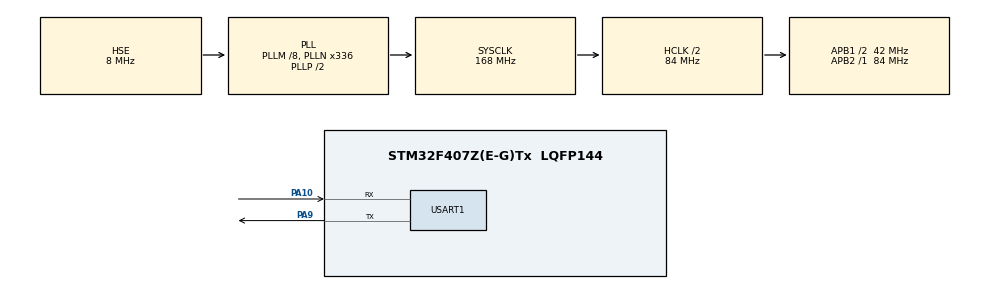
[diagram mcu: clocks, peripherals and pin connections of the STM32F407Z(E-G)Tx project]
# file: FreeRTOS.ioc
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FREERTOS.BinarySemaphores01=myBinarySem01,Dynamic,NULL
FREERTOS.Mutexes01=myMutex01,Dynamic,NULL
FREERTOS.Tasks01=defaultTask,0,512,StartDefaultTask,Default,NULL,Dynamic,NULL,NULL;myTask02,1,512,StartTask02,Default,NULL,Dynamic,NULL,NULL;myTask03,2,512,StartTask03,Default,NULL,Dynamic,NULL,NULL
FREERTOS.Timers01=myTimer01,Callback01,osTimerPeriodic,Default,NULL,Dynamic,NULL
FREERTOS.configTIMER_TASK_PRIORITY=5
FREERTOS.configUSE_TIMERS=1
Mcu.Family=STM32F4
Mcu.Name=STM32F407Z(E-G)Tx
Mcu.Package=LQFP144
NVIC.PriorityGroup=NVIC_PRIORITYGROUP_4
NVIC.TIM1_UP_TIM10_IRQn=true\:0\:0\:false\:false\:true\:false\:false\:true
NVIC.TimeBase=TIM1_UP_TIM10_IRQn
NVIC.TimeBaseIP=TIM1
NVIC.USART1_IRQn=true\:5\:0\:false\:false\:true\:true\:true\:true
PA10.Mode=Asynchronous
PA10.Signal=USART1_RX
PA9.Mode=Asynchronous
PA9.Signal=USART1_TX
PH0-OSC_IN.Mode=HSE-External-Oscillator
PH0-OSC_IN.Signal=RCC_OSC_IN
PH1-OSC_OUT.Mode=HSE-External-Oscillator
PH1-OSC_OUT.Signal=RCC_OSC_OUT
ProjectManager.HeapSize=0x200
ProjectManager.StackSize=0x400
ProjectManager.TargetToolchain=MDK-ARM V5.27
RCC.48MHZClocksFreq_Value=84000000
RCC.AHBCLKDivider=RCC_SYSCLK_DIV2
RCC.AHBFreq_Value=84000000
RCC.APB1CLKDivider=RCC_HCLK_DIV2
RCC.APB1Freq_Value=42000000
RCC.APB1TimFreq_Value=84000000
RCC.APB2Freq_Value=84000000
RCC.APB2TimFreq_Value=84000000
RCC.CortexFreq_Value=84000000
RCC.HCLKFreq_Value=84000000
RCC.HSE_VALUE=8000000
RCC.HSI_VALUE=16000000
RCC.LSE_VALUE=32768
RCC.PLLM=8
RCC.PLLN=336
RCC.PLLSourceVirtual=RCC_PLLSOURCE_HSE
RCC.SYSCLKFreq_VALUE=168000000
RCC.SYSCLKSource=RCC_SYSCLKSOURCE_PLLCLK
RCC.VCOOutputFreq_Value=336000000
USART1.VirtualMode=VM_ASYNC
VP_FREERTOS_VS_CMSIS_V1.Mode=CMSIS_V1
VP_SYS_VS_tim1.Mode=TIM1
board=custom

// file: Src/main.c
/* USER CODE BEGIN Header */
/**
  ******************************************************************************
  * @file           : main.c
  * @brief          : Main program body
  ******************************************************************************
  * @attention
  *
  * <h2><center>&copy; Copyright (c) 2020 STMicroelectronics.
  * All rights reserved.</center></h2>
  *
  * This software component is licensed by ST under Ultimate Liberty license
  * SLA0044, the "License"; You may not use this file except in compliance with
  * the License. You may obtain a copy of the License at:
  *                             www.st.com/SLA0044
  *
  ******************************************************************************
  */
/* USER CODE END Header */

#include "main.h"
#include "cmsis_os.h"
#include "usart.h"
#include "gpio.h"

void SystemClock_Config(void);
void MX_FREERTOS_Init(void);

int main(void)
{

  /* MCU Configuration--------------------------------------------------------*/

  /* Reset of all peripherals, Initializes the Flash interface and the Systick. */
  HAL_Init();

  /* Configure the system clock */
  SystemClock_Config();

  /* Initialize all configured peripherals */
  MX_GPIO_Init();
  MX_USART1_UART_Init();

  /* Call init function for freertos objects (in freertos.c) */
  MX_FREERTOS_Init();
  /* Start scheduler */
  osKernelStart();

  /* We should never get here as control is now taken by the scheduler */
  /* Infinite loop */
  while (1)
  {

  }
}

void SystemClock_Config(void)
{
  RCC_OscInitTypeDef RCC_OscInitStruct = {0};
  RCC_ClkInitTypeDef RCC_ClkInitStruct = {0};

  /** Configure the main internal regulator output voltage
  */
  __HAL_RCC_PWR_CLK_ENABLE();
  __HAL_PWR_VOLTAGESCALING_CONFIG(PWR_REGULATOR_VOLTAGE_SCALE1);
  /** Initializes the CPU, AHB and APB busses clocks
  */
  RCC_OscInitStruct.OscillatorType = RCC_OSCILLATORTYPE_HSE;
  RCC_OscInitStruct.HSEState = RCC_HSE_ON;
  RCC_OscInitStruct.PLL.PLLState = RCC_PLL_ON;
  RCC_OscInitStruct.PLL.PLLSource = RCC_PLLSOURCE_HSE;
  RCC_OscInitStruct.PLL.PLLM = 8;
  RCC_OscInitStruct.PLL.PLLN = 336;
  RCC_OscInitStruct.PLL.PLLP = RCC_PLLP_DIV2;
  RCC_OscInitStruct.PLL.PLLQ = 4;
  if (HAL_RCC_OscConfig(&RCC_OscInitStruct) != HAL_OK)
  {
    Error_Handler();
  }
  /** Initializes the CPU, AHB and APB busses clocks
  */
  RCC_ClkInitStruct.ClockType = RCC_CLOCKTYPE_HCLK|RCC_CLOCKTYPE_SYSCLK
                              |RCC_CLOCKTYPE_PCLK1|RCC_CLOCKTYPE_PCLK2;
  RCC_ClkInitStruct.SYSCLKSource = RCC_SYSCLKSOURCE_PLLCLK;
  RCC_ClkInitStruct.AHBCLKDivider = RCC_SYSCLK_DIV2;
  RCC_ClkInitStruct.APB1CLKDivider = RCC_HCLK_DIV2;
  RCC_ClkInitStruct.APB2CLKDivider = RCC_HCLK_DIV1;

  if (HAL_RCC_ClockConfig(&RCC_ClkInitStruct, FLASH_LATENCY_2) != HAL_OK)
  {
    Error_Handler();
  }
}

 /**
  * @brief  Period elapsed callback in non blocking mode
  * @note   This function is called  when TIM1 interrupt took place, inside
  * HAL_TIM_IRQHandler(). It makes a direct call to HAL_IncTick() to increment
  * a global variable "uwTick" used as application time base.
  * @param  htim : TIM handle
  * @retval None
  */
void HAL_TIM_PeriodElapsedCallback(TIM_HandleTypeDef *htim)
{
  if (htim->Instance == TIM1) {
    HAL_IncTick();
  }
}

void Error_Handler(void)
{
}

/************************ (C) COPYRIGHT STMicroelectronics *****END OF FILE****/

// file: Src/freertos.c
/* USER CODE BEGIN Header */
/**
  ******************************************************************************
  * File Name          : freertos.c
  * Description        : Code for freertos applications
  ******************************************************************************
  * @attention
  *
  * <h2><center>&copy; Copyright (c) 2020 STMicroelectronics.
  * All rights reserved.</center></h2>
  *
  * This software component is licensed by ST under Ultimate Liberty license
  * SLA0044, the "License"; You may not use this file except in compliance with
  * the License. You may obtain a copy of the License at:
  *                             www.st.com/SLA0044
  *
  ******************************************************************************
  */
/* USER CODE END Header */

#include "FreeRTOS.h"
#include "task.h"
#include "main.h"
#include "cmsis_os.h"

/* USER CODE BEGIN Includes */
#include "usart.h"
/* USER CODE END Includes */

/* USER CODE BEGIN Variables */
EventGroupHandle_t Event_Handle =NULL;//事件标志组
/* USER CODE END Variables */
osThreadId defaultTaskHandle;
osThreadId myTask02Handle;
osThreadId myTask03Handle;
osTimerId myTimer01Handle;					//软件定时器
osMutexId myMutex01Handle;					//互斥信号量
osSemaphoreId myBinarySem01Handle;	//二值信号量

/* USER CODE BEGIN FunctionPrototypes */
#define EVENT  (0x01 << 7)//设置事件掩码的位1
/* USER CODE END FunctionPrototypes */

void StartDefaultTask(void const * argument);
void StartTask02(void const * argument);
void StartTask03(void const * argument);
void Callback01(void const * argument);

void MX_FREERTOS_Init(void); /* (MISRA C 2004 rule 8.1) */

/* GetIdleTaskMemory prototype (linked to static allocation support) */
void vApplicationGetIdleTaskMemory( StaticTask_t **ppxIdleTaskTCBBuffer, StackType_t **ppxIdleTaskStackBuffer, uint32_t *pulIdleTaskStackSize );

/* GetTimerTaskMemory prototype (linked to static allocation support) */
void vApplicationGetTimerTaskMemory( StaticTask_t **ppxTimerTaskTCBBuffer, StackType_t **ppxTimerTaskStackBuffer, uint32_t *pulTimerTaskStackSize );

/* USER CODE BEGIN GET_IDLE_TASK_MEMORY */
static StaticTask_t xIdleTaskTCBBuffer;
static StackType_t xIdleStack[configMINIMAL_STACK_SIZE];

void vApplicationGetIdleTaskMemory( StaticTask_t **ppxIdleTaskTCBBuffer, StackType_t **ppxIdleTaskStackBuffer, uint32_t *pulIdleTaskStackSize )
{
  *ppxIdleTaskTCBBuffer = &xIdleTaskTCBBuffer;
  *ppxIdleTaskStackBuffer = &xIdleStack[0];
  *pulIdleTaskStackSize = configMINIMAL_STACK_SIZE;
  /* place for user code */
}
/* USER CODE END GET_IDLE_TASK_MEMORY */

/* USER CODE BEGIN GET_TIMER_TASK_MEMORY */
static StaticTask_t xTimerTaskTCBBuffer;
static StackType_t xTimerStack[configTIMER_TASK_STACK_DEPTH];

void vApplicationGetTimerTaskMemory( StaticTask_t **ppxTimerTaskTCBBuffer, StackType_t **ppxTimerTaskStackBuffer, uint32_t *pulTimerTaskStackSize )
{
  *ppxTimerTaskTCBBuffer = &xTimerTaskTCBBuffer;
  *ppxTimerTaskStackBuffer = &xTimerStack[0];
  *pulTimerTaskStackSize = configTIMER_TASK_STACK_DEPTH;
  /* place for user code */
}
/* USER CODE END GET_TIMER_TASK_MEMORY */

void MX_FREERTOS_Init(void) {
  /* Create the mutex(es) */
  /* definition and creation of myMutex01 */
  osMutexDef(myMutex01);
  myMutex01Handle = osMutexCreate(osMutex(myMutex01));

  /* Create the semaphores(s) */
  /* definition and creation of myBinarySem01 */
  osSemaphoreDef(myBinarySem01);
  myBinarySem01Handle = osSemaphoreCreate(osSemaphore(myBinarySem01), 1);

  /* Create the timer(s) */
  /* definition and creation of myTimer01 */
  osTimerDef(myTimer01, Callback01);
  myTimer01Handle = osTimerCreate(osTimer(myTimer01), osTimerPeriodic, NULL);

  /* Create the thread(s) */
  /* definition and creation of defaultTask */
  osThreadDef(defaultTask, StartDefaultTask, osPriorityNormal, 0, 512);
  defaultTaskHandle = osThreadCreate(osThread(defaultTask), NULL);

  /* definition and creation of myTask02 */
  osThreadDef(myTask02, StartTask02, osPriorityAboveNormal, 0, 512);
  myTask02Handle = osThreadCreate(osThread(myTask02), NULL);

  /* definition and creation of myTask03 */
  osThreadDef(myTask03, StartTask03, osPriorityHigh, 0, 512);
  myTask03Handle = osThreadCreate(osThread(myTask03), NULL);

  /* USER CODE BEGIN RTOS_THREADS */
  /* add threads, ... */
  Event_Handle = xEventGroupCreate();
  if(NULL != Event_Handle)
    printf("Event_Handle 事件创建成功!\r\n");
  /* USER CODE END RTOS_THREADS */

}

void StartDefaultTask(void const * argument)
{
  /* USER CODE BEGIN StartDefaultTask */
  /* Infinite loop */
  for(;;)
  {
		printf("任务1等待互斥信号量\n");
		osMutexWait(myMutex01Handle,osWaitForever);
//		osSemaphoreWait(myBinarySem01Handle,osWaitForever);  //等待二值信号量
		printf("任务1接收到互斥信号量\n");
		osDelay(5000);
		printf("任务1释放互斥信号量\n");
		osMutexRelease(myMutex01Handle);
//		osSemaphoreRelease(myBinarySem01Handle,osWaitForever); //释放二值信号量
  }
  /* USER CODE END StartDefaultTask */
}

void StartTask02(void const * argument)
{
  /* USER CODE BEGIN StartTask02 */
	EventBits_t r_event;  /* 定义一个事件接收变量 */
  /* Infinite loop */
  for(;;)
  {
    /*******************************************************************
     * 等待接收事件标志
     *
     * 如果xClearOnExit设置为pdTRUE，那么在xEventGroupWaitBits()返回之前，
     * 如果满足等待条件（如果函数返回的原因不是超时），那么在事件组中设置
     * 的uxBitsToWaitFor中的任何位都将被清除。
     * 如果xClearOnExit设置为pdFALSE，
     * 则在调用xEventGroupWaitBits()时，不会更改事件组中设置的位。
     *
     * xWaitForAllBits如果xWaitForAllBits设置为pdTRUE，则当uxBitsToWaitFor中
     * 的所有位都设置或指定的块时间到期时，xEventGroupWaitBits()才返回。
     * 如果xWaitForAllBits设置为pdFALSE，则当设置uxBitsToWaitFor中设置的任何
     * 一个位置1 或指定的块时间到期时，xEventGroupWaitBits()都会返回。
     * 阻塞时间由xTicksToWait参数指定。
      *********************************************************/
    r_event = xEventGroupWaitBits(Event_Handle,  /* 事件对象句柄 */
                                  EVENT,/* 接收线程感兴趣的事件 */
                                  pdTRUE,   /* 退出时清除事件位 */
                                  pdTRUE,   /* 满足感兴趣的所有事件 */
                                  portMAX_DELAY);/* 指定超时事件,一直等 */
		if((r_event & EVENT) == EVENT)
		{
			printf("\n\r清空任务事件标志组\n\r");
			xEventGroupClearBits(Event_Handle,EVENT);
		}
//		printf("任务2正在进行\n");
//    osDelay(1000);
  }
  /* USER CODE END StartTask02 */
}

void StartTask03(void const * argument)
{
  /* USER CODE BEGIN StartTask03 */
  /* Infinite loop */
  for(;;)
  {
		printf("\n\r开启软件定时器,1s进入一次回调函数\n\r");
		osTimerStart(myTimer01Handle,1000);
		printf("任务3等待互斥信号量\n");
		osMutexWait(myMutex01Handle,osWaitForever);
		printf("任务3接收到互斥信号量\n");
		printf("任务3释放互斥信号量\n");
		osMutexRelease(myMutex01Handle);
    osDelay(1000);
		xEventGroupCreate();
  }
  /* USER CODE END StartTask03 */
}

/* Callback01 function */
void Callback01(void const * argument)		//软件定时器回调函数
{
  /* USER CODE BEGIN Callback01 */
	static uint8_t NumberCount;
	NumberCount++;
	if(NumberCount==5){
		NumberCount=0;
		xEventGroupSetBits(Event_Handle,EVENT);
	}
  printf("\n\r进入软件定时器回调函数\n\r");
  /* USER CODE END Callback01 */
}

/************************ (C) COPYRIGHT STMicroelectronics *****END OF FILE****/
